# STM32F479 register map
File version: 2.0
CPU: CM4 r0p1, little endian, MPU, FPU, 4 interrupt priority bits
Registers are 32-bit, read-write, reset 0x0 unless marked. A register's access mark holds for its fields unless they carry their own. Offsets are from the block's base; [hi:lo] are bit positions.

## OTG_FS_PWRCLK — USB on the go full speed
Base 0x50000E00
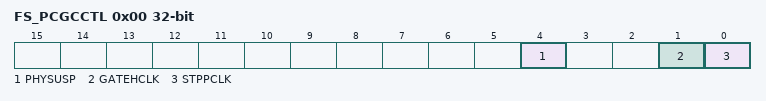
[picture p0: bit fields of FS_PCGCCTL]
0x00 FS_PCGCCTL — OTG_FS power and clock gating control register (OTG_FS_PCGCCTL)
  [4] PHYSUSP — PHY Suspended
  [1] GATEHCLK
  [0] STPPCLK — Stop PHY clock

## OTG_HS_PWRCLK — USB on the go high speed
Base 0x40040E00
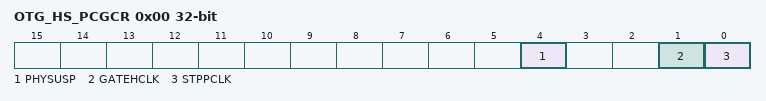
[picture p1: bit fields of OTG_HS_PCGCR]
0x00 OTG_HS_PCGCR — Power and clock gating control register
  [4] PHYSUSP — PHY suspended
  [1] GATEHCLK
  [0] STPPCLK — Stop PHY clock

## PWR — Power control
Base 0x40007000
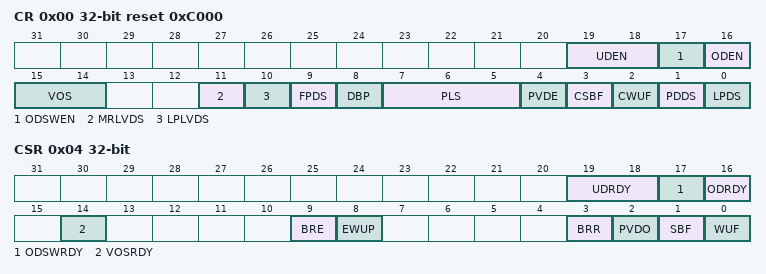
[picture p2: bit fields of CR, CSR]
0x00 CR reset 0xC000 — power control register
  [19:18] UDEN — Under-drive enable in stop mode
  [17] ODSWEN — Over-drive switching enabled
  [16] ODEN — Over-drive enable
  [15:14] VOS — Regulator voltage scaling output selection
  [11] MRLVDS — Main regulator low voltage in deepsleep mode
  [10] LPLVDS — Low-Power Regulator Low Voltage in deepsleep
  [9] FPDS — Flash power down in Stop mode
  [8] DBP — Disable backup domain write protection
  [7:5] PLS — PVD level selection
  [4] PVDE — Power voltage detector enable
  [3] CSBF — Clear standby flag
  [2] CWUF — Clear wakeup flag
  [1] PDDS — Power down deepsleep
  [0] LPDS — Low-power deep sleep
0x04 CSR access per field — power control/status register
  [19:18] UDRDY rw — Under-drive ready flag
  [17] ODSWRDY ro — Over-drive mode switching ready
  [16] ODRDY ro — Over-drive mode ready
  [14] VOSRDY rw — Regulator voltage scaling output selection ready bit
  [9] BRE rw — Backup regulator enable
  [8] EWUP rw — Enable WKUP pin
  [3] BRR ro — Backup regulator ready
  [2] PVDO ro — PVD output
  [1] SBF ro — Standby flag
  [0] WUF ro — Wakeup flag

## QUADSPI — QuadSPI interface
Base 0xA0001000
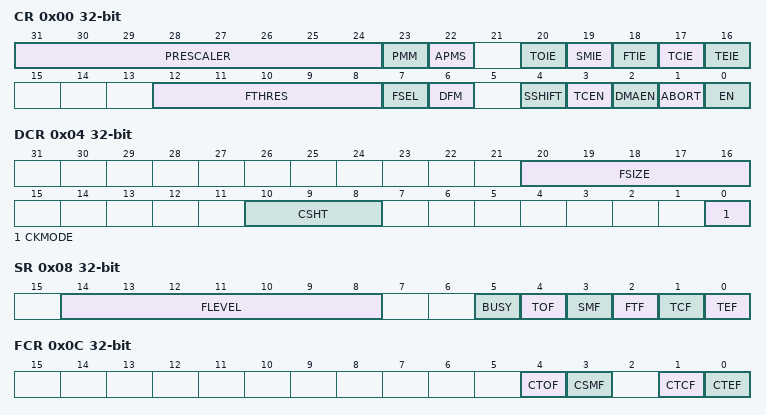
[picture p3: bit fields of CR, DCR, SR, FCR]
0x00 CR — control register
  [31:24] PRESCALER — Clock prescaler
  [23] PMM — Polling match mode
  [22] APMS — Automatic poll mode stop
  [20] TOIE — TimeOut interrupt enable
  [19] SMIE — Status match interrupt enable
  [18] FTIE — FIFO threshold interrupt enable
  [17] TCIE — Transfer complete interrupt enable
  [16] TEIE — Transfer error interrupt enable
  [12:8] FTHRES — IFO threshold level
  [7] FSEL — FLASH memory selection
  [6] DFM — Dual-flash mode
  [4] SSHIFT — Sample shift
  [3] TCEN — Timeout counter enable
  [2] DMAEN — DMA enable
  [1] ABORT — Abort request
  [0] EN — Enable
0x04 DCR — device configuration register
  [20:16] FSIZE — FLASH memory size
  [10:8] CSHT — Chip select high time
  [0] CKMODE — Mode 0 / mode 3
0x08 SR ro — status register
  [14:8] FLEVEL — FIFO level
  [5] BUSY
  [4] TOF — Timeout flag
  [3] SMF — Status match flag
  [2] FTF — FIFO threshold flag
  [1] TCF — Transfer complete flag
  [0] TEF — Transfer error flag
0x0C FCR — flag clear register
  [4] CTOF — Clear timeout flag
  [3] CSMF — Clear status match flag
  [1] CTCF — Clear transfer complete flag
  [0] CTEF — Clear transfer error flag
0x10 DLR — data length register
  [31:0] DL — Data length
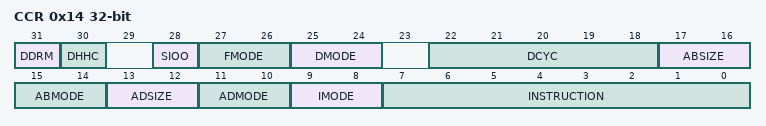
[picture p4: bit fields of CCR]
0x14 CCR — communication configuration register
  [31] DDRM — Double data rate mode
  [30] DHHC — DDR hold half cycle
  [28] SIOO — Send instruction only once mode
  [27:26] FMODE — Functional mode
  [25:24] DMODE — Data mode
  [22:18] DCYC — Number of dummy cycles
  [17:16] ABSIZE — Alternate bytes size
  [15:14] ABMODE — Alternate bytes mode
  [13:12] ADSIZE — Address size
  [11:10] ADMODE — Address mode
  [9:8] IMODE — Instruction mode
  [7:0] INSTRUCTION
0x18 AR — address register
  [31:0] ADDRESS
0x1C ABR
  [31:0] ALTERNATE
0x20 DR — data register
  [31:0] DATA
0x24 PSMKR — polling status mask register
  [31:0] MASK — Status mask
0x28 PSMAR — polling status match register
  [31:0] MATCH — Status match
0x2C PIR — polling interval register
  [15:0] INTERVAL — Polling interval
0x30 LPTR — low-power timeout register
  [15:0] TIMEOUT — Timeout period
